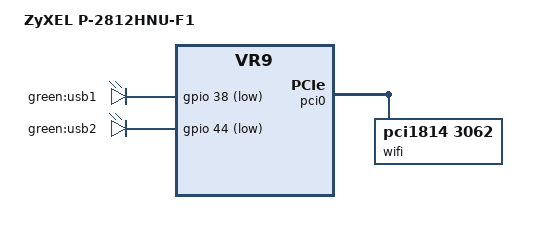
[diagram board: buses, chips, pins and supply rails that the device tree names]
// SPDX-License-Identifier: GPL-2.0-or-later OR MIT
#include "vr9_zyxel_p-2812hnu-f1.dtsi"

/ {
	compatible = "zyxel,p-2812hnu-f1", "zyxel,p-2812hnu", "lantiq,xway", "lantiq,vr9";
	model = "ZyXEL P-2812HNU-F1";

	leds {
		usb1 {
			label = "green:usb1";
			gpios = <&gpio 38 GPIO_ACTIVE_LOW>;
			trigger-sources = <&ehci_port1>;
			linux,default-trigger = "usbport";
		};
		usb2 {
			label = "green:usb2";
			gpios = <&gpio 44 GPIO_ACTIVE_LOW>;
			trigger-sources = <&ehci_port2>;
			linux,default-trigger = "usbport";
		};
	};
};

&pci0 {
	wifi@1814,3062 {
		compatible = "pci1814,3062";
		reg = <0x7000 0 0 0 0>;
		ralink,eeprom = "RT3062.eeprom";
	};
};

&pcie0 {
	status = "disabled";
};
